# STM32H7RSxx register map
File version: 0.2
CPU: CM7 r0p1, little endian, MPU, FPU, 4 interrupt priority bits
Registers are 32-bit, read-write, reset 0x0 unless marked. A register's access mark holds for its fields unless they carry their own. Offsets are from the block's base; [hi:lo] are bit positions; lines under a group give offsets from that group; {n}, {i} and the like mark numbered series; 'fields as' and 'values as' point back to an identical list; <NAME> marks a mode.

## ADC1 — ADC register block
Base 0x40022000
Same registers: ADC2 0x40022100
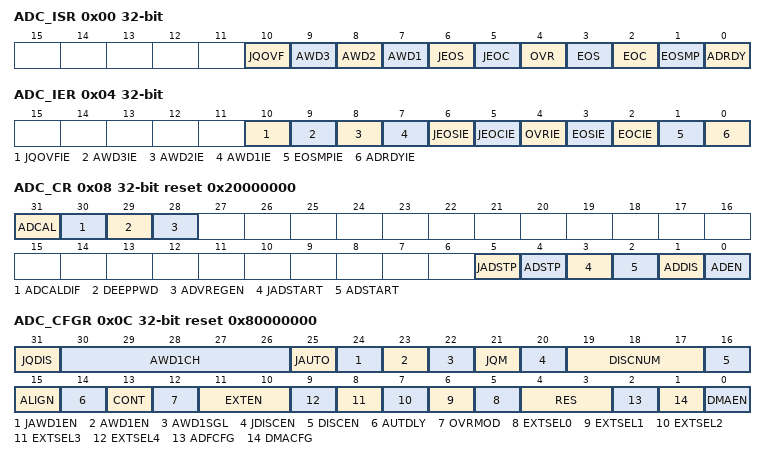
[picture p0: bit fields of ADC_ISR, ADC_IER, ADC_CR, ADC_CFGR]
0x00 ADC_ISR — ADC interrupt and status register
  [10] JQOVF — Injected context queue overflow This bit is set by hardware when an Overflow of the Injected Queue of Context occurs. It is cleared by software writing 1 to it. Refer to Section 25.4.21: Queue of context for injected conversions for more information.
    0=No injected context queue overflow occurred (or the flag event was already acknowledged and cleared by software); 1=Injected context queue overflow has occurred
  [9] AWD3 — Analog watchdog 3 flag This bit is set by hardware when the converted voltage crosses the values programmed in the fields LT3[7:0] and HT3[7:0] of ADC_TR3 register. It is cleared by software writing 1 to it.
    0=No analog watchdog 3 event occurred (or the flag event was already acknowledged and cleared by software); 1=Analog watchdog 3 event occurred
  [8] AWD2 — Analog watchdog 2 flag This bit is set by hardware when the converted voltage crosses the values programmed in the fields LT2[7:0] and HT2[7:0] of ADC_TR2 register. It is cleared by software writing 1 to it.
    0=No analog watchdog 2 event occurred (or the flag event was already acknowledged and cleared by software); 1=Analog watchdog 2 event occurred
  [7] AWD1 — Analog watchdog 1 flag This bit is set by hardware when the converted voltage crosses the values programmed in the fields LT1[11:0] and HT1[11:0] of ADC_TR1 register. It is cleared by software. writing 1 to it.
    0=No analog watchdog 1 event occurred (or the flag event was already acknowledged and cleared by software); 1=Analog watchdog 1 event occurred
  [6] JEOS — Injected channel end of sequence flag This bit is set by hardware at the end of the conversions of all injected channels in the group. It is cleared by software writing 1 to it.
    0=Injected conversion sequence not complete (or the flag event was already acknowledged and cleared by software); 1=Injected conversions complete
  [5] JEOC — Injected channel end of conversion flag This bit is set by hardware at the end of each injected conversion of a channel when a new data is available in the corresponding ADC_JDRy register. It is cleared by software writing 1 to it or by reading the corresponding ADC_JDRy register
    0=Injected channel conversion not complete (or the flag event was already acknowledged and cleared by software); 1=Injected channel conversion complete
  [4] OVR — ADC overrun This bit is set by hardware when an overrun occurs on a regular channel, meaning that a new conversion has completed while the EOC flag was already set. It is cleared by software writing 1 to it.
    0=No overrun occurred (or the flag event was already acknowledged and cleared by software); 1=Overrun has occurred
  [3] EOS — End of regular sequence flag This bit is set by hardware at the end of the conversions of a regular sequence of channels. It is cleared by software writing 1 to it.
    0=Regular Conversions sequence not complete (or the flag event was already acknowledged and cleared by software); 1=Regular Conversions sequence complete
  [2] EOC — End of conversion flag This bit is set by hardware at the end of each regular conversion of a channel when a new data is available in the ADC_DR register. It is cleared by software writing 1 to it or by reading the ADC_DR register
    0=Regular channel conversion not complete (or the flag event was already acknowledged and cleared by software); 1=Regular channel conversion complete
  [1] EOSMP — End of sampling flag This bit is set by hardware during the conversion of any channel (only for regular channels), at the end of the sampling phase.
    0=not at the end of the sampling phase (or the flag event was already acknowledged and cleared by software); 1=End of sampling phase reached
  [0] ADRDY — ADC ready This bit is set by hardware after the ADC has been enabled (ADEN = 1) and when the ADC reaches a state where it is ready to accept conversion requests. It is cleared by software writing 1 to it.
    0=ADC not yet ready to start conversion (or the flag event was already acknowledged and cleared by software); 1=ADC is ready to start conversion
0x04 ADC_IER — ADC interrupt enable register
  [10] JQOVFIE — Injected context queue overflow interrupt enable This bit is set and cleared by software to enable/disable the Injected Context Queue Overflow interrupt. Note: The software is allowed to write this bit only when JADSTART = 0 (which ensures that no injected conversion is ongoing).
    0=Injected Context Queue Overflow interrupt disabled; 1=Injected Context Queue Overflow interrupt enabled. An interrupt is generated when the JQOVF bit is set.
  [9] AWD3IE — Analog watchdog 3 interrupt enable This bit is set and cleared by software to enable/disable the analog watchdog 2 interrupt. Note: The software is allowed to write this bit only when ADSTART = 0 and JADSTART = 0 (which ensures that no conversion is ongoing).
    0=Analog watchdog 3 interrupt disabled; 1=Analog watchdog 3 interrupt enabled
  [8] AWD2IE — Analog watchdog 2 interrupt enable This bit is set and cleared by software to enable/disable the analog watchdog 2 interrupt. Note: The software is allowed to write this bit only when ADSTART = 0 and JADSTART = 0 (which ensures that no conversion is ongoing).
    0=Analog watchdog 2 interrupt disabled; 1=Analog watchdog 2 interrupt enabled
  [7] AWD1IE — Analog watchdog 1 interrupt enable This bit is set and cleared by software to enable/disable the analog watchdog 1 interrupt. Note: The software is allowed to write this bit only when ADSTART = 0 and JADSTART = 0 (which ensures that no conversion is ongoing).
    0=Analog watchdog 1 interrupt disabled; 1=Analog watchdog 1 interrupt enabled
  [6] JEOSIE — End of injected sequence of conversions interrupt enable This bit is set and cleared by software to enable/disable the end of injected sequence of conversions interrupt. Note: The software is allowed to write this bit only when JADSTART = 0 (which ensures that no injected conversion is ongoing).
    0=JEOS interrupt disabled; 1=JEOS interrupt enabled. An interrupt is generated when the JEOS bit is set.
  [5] JEOCIE — End of injected conversion interrupt enable This bit is set and cleared by software to enable/disable the end of an injected conversion interrupt. Note: The software is allowed to write this bit only when JADSTART = 0 (which ensures that no injected conversion is ongoing).
    0=JEOC interrupt disabled; 1=JEOC interrupt enabled. An interrupt is generated when the JEOC bit is set.
  [4] OVRIE — Overrun interrupt enable This bit is set and cleared by software to enable/disable the Overrun interrupt of a regular conversion. Note: The software is allowed to write this bit only when ADSTART = 0 (which ensures that no regular conversion is ongoing).
    0=Overrun interrupt disabled; 1=Overrun interrupt enabled. An interrupt is generated when the OVR bit is set.
  [3] EOSIE — End of regular sequence of conversions interrupt enable This bit is set and cleared by software to enable/disable the end of regular sequence of conversions interrupt. Note: The software is allowed to write this bit only when ADSTART = 0 (which ensures that no regular conversion is ongoing).
    0=EOS interrupt disabled; 1=EOS interrupt enabled. An interrupt is generated when the EOS bit is set.
  [2] EOCIE — End of regular conversion interrupt enable This bit is set and cleared by software to enable/disable the end of a regular conversion interrupt. Note: The software is allowed to write this bit only when ADSTART = 0 (which ensures that no regular conversion is ongoing).
    0=EOC interrupt disabled; 1=EOC interrupt enabled. An interrupt is generated when the EOC bit is set.
  [1] EOSMPIE — End of sampling flag interrupt enable for regular conversions This bit is set and cleared by software to enable/disable the end of the sampling phase interrupt for regular conversions. Note: The software is allowed to write this bit only when ADSTART = 0 (which ensures that no regular conversion is ongoing).
    0=EOSMP interrupt disabled; 1=EOSMP interrupt enabled. An interrupt is generated when the EOSMP bit is set.
  [0] ADRDYIE — ADC ready interrupt enable This bit is set and cleared by software to enable/disable the ADC Ready interrupt. Note: The software is allowed to write this bit only when ADSTART = 0 and JADSTART = 0 (which ensures that no conversion is ongoing).
    0=ADRDY interrupt disabled; 1=ADRDY interrupt enabled. An interrupt is generated when the ADRDY bit is set.
0x08 ADC_CR reset 0x20000000 — ADC control register
  [31] ADCAL — ADC calibration This bit is set by software to start the calibration of the ADC. Program first the bit ADCALDIF to determine if this calibration applies for Single-ended or Differential inputs mode. It is cleared by hardware after calibration is complete. Note: The software is allowed to launch a calibration by setting ADCAL only when ADEN = 0. Note: The software is allowed to update the calibration factor by writing ADC_CALFACT only when ADEN = 1 and ADSTART = 0 and JADSTART = 0 (ADC enabled and no conversion is ongoing)
    0=Calibration complete; 1=Write 1 to calibrate the ADC. Read at 1 means that a calibration in progress.
  [30] ADCALDIF — Differential mode for calibration This bit is set and cleared by software to configure the Single-ended or Differential inputs mode for the calibration. Note: The software is allowed to write this bit only when the ADC is disabled and is not calibrating (ADCAL = 0, JADSTART = 0, JADSTP = 0, ADSTART = 0, ADSTP = 0, ADDIS = 0 and ADEN = 0).
    0=Writing ADCAL launches a calibration in Single-ended inputs mode; 1=Writing ADCAL launches a calibration in Differential inputs mode
  [29] DEEPPWD — Deep-power-down enable This bit is set and cleared by software to put the ADC in Deep-power-down mode. Note: The software is allowed to write this bit only when the ADC is disabled (ADCAL = 0, JADSTART = 0, JADSTP = 0, ADSTART = 0, ADSTP = 0, ADDIS = 0 and ADEN = 0).
    0=ADC not in Deep-power down; 1=ADC in Deep-power-down (default reset state)
  [28] ADVREGEN — ADC voltage regulator enable This bits is set by software to enable the ADC voltage regulator. Before performing any operation such as launching a calibration or enabling the ADC, the ADC voltage regulator must first be enabled and the software must wait for the regulator start-up time. For more details about the ADC voltage regulator enable and disable sequences, refer to Section 25.4.6: ADC Deep-power-down mode (DEEPPWD) and ADC voltage regulator (ADVREGEN). The software can program this bit field only when the ADC is disabled (ADCAL = 0, JADSTART = 0, ADSTART = 0, ADSTP = 0, ADDIS = 0 and ADEN = 0).
    0=ADC Voltage regulator disabled; 1=ADC Voltage regulator enabled
  [5] JADSTP — ADC stop of injected conversion command This bit is set by software to stop and discard an ongoing injected conversion (JADSTP Command). It is cleared by hardware when the conversion is effectively discarded and the ADC injected sequence and triggers can be re-configured. The ADC is then ready to accept a new start of injected conversions (JADSTART command). Note: The software is allowed to set JADSTP only when JADSTART = 1 and ADDIS = 0 (ADC is enabled and eventually converting an injected conversion and there is no pending request to disable the ADC) Note: In Auto-injection mode (JAUTO = 1), setting ADSTP bit aborts both regular and injected conversions (do not use JADSTP)
    0=No ADC stop injected conversion command ongoing; 1=Write 1 to stop injected conversions ongoing. Read 1 means that an ADSTP command is in progress.
  [4] ADSTP — ADC stop of regular conversion command This bit is set by software to stop and discard an ongoing regular conversion (ADSTP Command). It is cleared by hardware when the conversion is effectively discarded and the ADC regular sequence and triggers can be re-configured. The ADC is then ready to accept a new start of regular conversions (ADSTART command). Note: The software is allowed to set ADSTP only when ADSTART = 1 and ADDIS = 0 (ADC is enabled and eventually converting a regular conversion and there is no pending request to disable the ADC). In auto-injection mode (JAUTO = 1), setting ADSTP bit aborts both regular and injected conversions (do not use JADSTP).
    0=No ADC stop regular conversion command ongoing; 1=Write 1 to stop regular conversions ongoing. Read 1 means that an ADSTP command is in progress.
  [3] JADSTART — ADC start of injected conversion This bit is set by software to start ADC conversion of injected channels. Depending on the configuration bits JEXTEN, a conversion immediately starts (software trigger configuration) or once an injected hardware trigger event occurs (hardware trigger configuration). It is cleared by hardware: in Single conversion mode when software trigger is selected (JEXTSEL = 0x0): at the assertion of the End of Injected Conversion Sequence (JEOS) flag. in all cases: after the execution of the JADSTP command, at the same time that JADSTP is cleared by hardware. Note: The software is allowed to set JADSTART only when ADEN = 1 and ADDIS = 0 (ADC is enabled and there is no pending request to disable the ADC). Note: In auto-injection mode (JAUTO = 1), regular and auto-injected conversions are started by setting bit ADSTART (JADSTART must be kept cleared)
    0=No ADC injected conversion is ongoing; 1=Write 1 to start injected conversions. Read 1 means that the ADC is operating and eventually converting an injected channel.
  [2] ADSTART — ADC start of regular conversion This bit is set by software to start ADC conversion of regular channels. Depending on the configuration bits EXTEN, a conversion immediately starts (software trigger configuration) or once a regular hardware trigger event occurs (hardware trigger configuration). It is cleared by hardware: in Single conversion mode when software trigger is selected (EXTSEL = 0x0): at the assertion of the End of Regular Conversion Sequence (EOS) flag. in all cases: after the execution of the ADSTP command, at the same time that ADSTP is cleared by hardware. Note: The software is allowed to set ADSTART only when ADEN = 1 and ADDIS = 0 (ADC is enabled and there is no pending request to disable the ADC) Note: In auto-injection mode (JAUTO = 1), regular and auto-injected conversions are started by setting bit ADSTART (JADSTART must be kept cleared)
    0=No ADC regular conversion is ongoing; 1=Write 1 to start regular conversions. Read 1 means that the ADC is operating and eventually converting a regular channel.
  [1] ADDIS — ADC disable command This bit is set by software to disable the ADC (ADDIS command) and put it into power-down state (OFF state). It is cleared by hardware once the ADC is effectively disabled (ADEN is also cleared by hardware at this time). Note: The software is allowed to set ADDIS only when ADEN = 1 and both ADSTART = 0 and JADSTART = 0 (which ensures that no conversion is ongoing)
    0=no ADDIS command ongoing; 1=Write 1 to disable the ADC. Read 1 means that an ADDIS command is in progress.
  [0] ADEN — ADC enable control This bit is set by software to enable the ADC. The ADC is effectively ready to operate once the flag ADRDY has been set. It is cleared by hardware when the ADC is disabled, after the execution of the ADDIS command. Note: The software is allowed to set ADEN only when all bits of ADC_CR registers are 0 (ADCAL = 0, JADSTART = 0, ADSTART = 0, ADSTP = 0, ADDIS = 0 and ADEN = 0) except for bit ADVREGEN which must be 1 (and the software must have wait for the startup time of the voltage regulator)
    0=ADC is disabled (OFF state); 1=Write 1 to enable the ADC
0x0C ADC_CFGR reset 0x80000000 — ADC configuration register
  [31] JQDIS — Injected queue disable This bit is set and cleared by software to disable the injected queue mechanism: Note: The software is allowed to write this bit only when ADSTART = 0 and JADSTART = 0 (which ensures that no regular nor injected conversion is ongoing). Note: A set or reset of JQDIS bit causes the injected queue to be flushed and the JSQR register is cleared.
    0=Injected queue enabled; 1=Injected queue disabled
  [30:26] AWD1CH — Analog watchdog 1 channel selection These bits are set and cleared by software. They select the input channel to be guarded by the analog watchdog. ..... others: reserved, must not be used Note: Some channels are not connected physically. Keep the corresponding AWD1CH[4:0] setting to the reset value. Note: The channel selected by AWD1CH must be also selected into the SQRi or JSQRi registers. Note: The software is allowed to write these bits only when ADSTART = 0 and JADSTART = 0 (which ensures that no conversion is ongoing).
    0=ADC analog input channel 0 monitored by AWD1 (available on ADC1 only); 1=ADC analog input channel 1 monitored by AWD1; 18=ADC analog input channel 18 monitored by AWD1
  [25] JAUTO — Automatic injected group conversion This bit is set and cleared by software to enable/disable automatic injected group conversion after regular group conversion. Note: The software is allowed to write this bit only when ADSTART = 0 and JADSTART = 0 (which ensures that no regular nor injected conversion is ongoing). Note: When dual mode is enabled (DUAL bits in ADC_CCR register are not equal to zero), the bit JAUTO of the slave ADC is no more writable and its content is equal to the bit JAUTO of the master ADC.
    0=Automatic injected group conversion disabled; 1=Automatic injected group conversion enabled
  [24] JAWD1EN — Analog watchdog 1 enable on injected channels This bit is set and cleared by software Note: The software is allowed to write this bit only when JADSTART = 0 (which ensures that no injected conversion is ongoing).
    0=Analog watchdog 1 disabled on injected channels; 1=Analog watchdog 1 enabled on injected channels
  [23] AWD1EN — Analog watchdog 1 enable on regular channels This bit is set and cleared by software Note: The software is allowed to write this bit only when ADSTART = 0 (which ensures that no regular conversion is ongoing).
    0=Analog watchdog 1 disabled on regular channels; 1=Analog watchdog 1 enabled on regular channels
  [22] AWD1SGL — Enable the watchdog 1 on a single channel or on all channels This bit is set and cleared by software to enable the analog watchdog on the channel identified by the AWD1CH[4:0] bits or on all the channels Note: The software is allowed to write these bits only when ADSTART = 0 and JADSTART = 0 (which ensures that no conversion is ongoing).
    0=Analog watchdog 1 enabled on all channels; 1=Analog watchdog 1 enabled on a single channel
  [21] JQM — JSQR queue mode This bit is set and cleared by software. It defines how an empty Queue is managed. Refer to Section 25.4.21: Queue of context for injected conversions for more information. Note: The software is allowed to write this bit only when JADSTART = 0 (which ensures that no injected conversion is ongoing). Note: When dual mode is enabled (DUAL bits in ADC_CCR register are not equal to zero), the bit JQM of the slave ADC is no more writable and its content is equal to the bit JQM of the master ADC.
    0=JSQR mode 0: The Queue is never empty and maintains the last written configuration into JSQR; 1=JSQR mode 1: The Queue can be empty and when this occurs, the software and hardware triggers of the injected sequence are both internally disabled just after the completion of the last valid injected sequence
  [20] JDISCEN — Discontinuous mode on injected channels This bit is set and cleared by software to enable/disable Discontinuous mode on the injected channels of a group. Note: The software is allowed to write this bit only when JADSTART = 0 (which ensures that no injected conversion is ongoing). Note: It is not possible to use both auto-injected mode and Discontinuous mode simultaneously: the bits DISCEN and JDISCEN must be kept cleared by software when JAUTO is set. Note: When dual mode is enabled (bits DUAL of ADC_CCR register are not equal to zero), the bit JDISCEN of the slave ADC is no more writable and its content is equal to the bit JDISCEN of the master ADC.
    0=Discontinuous mode on injected channels disabled; 1=Discontinuous mode on injected channels enabled
  [19:17] DISCNUM — Discontinuous mode channel count These bits are written by software to define the number of regular channels to be converted in Discontinuous mode, after receiving an external trigger. ... Note: The software is allowed to write these bits only when ADSTART = 0 (which ensures that no regular conversion is ongoing). Note: When dual mode is enabled (DUAL bits in ADC_CCR register are not equal to zero), the bits DISCNUM[2:0] of the slave ADC are no more writable and their content is equal to the bits DISCNUM[2:0] of the master ADC.
    0=1 channel; 1=2 channels; 7=8 channels
  [16] DISCEN — Discontinuous mode for regular channels This bit is set and cleared by software to enable/disable Discontinuous mode for regular channels. Note: It is not possible to have both Discontinuous mode and Continuous mode enabled: it is forbidden to set both DISCEN = 1 and CONT = 1. Note: It is not possible to use both auto-injected mode and Discontinuous mode simultaneously: the bits DISCEN and JDISCEN must be kept cleared by software when JAUTO is set. Note: The software is allowed to write this bit only when ADSTART = 0 (which ensures that no regular conversion is ongoing). Note: When dual mode is enabled (DUAL bits in ADC_CCR register are not equal to zero), the bit DISCEN of the slave ADC is no more writable and its content is equal to the bit DISCEN of the master ADC.
    0=Discontinuous mode for regular channels disabled; 1=Discontinuous mode for regular channels enabled
  [15] ALIGN — Data alignment This bit is set and cleared by software to select right or left alignment. Refer to Section : Data register, data alignment and offset (ADC_DR, OFFSET, OFFSET_CH, ALIGN). Note: The software is allowed to write this bit only when ADSTART = 0 and JADSTART = 0 (which ensures that no conversion is ongoing).
    0=Right alignment; 1=Left alignment
  [14] AUTDLY — Delayed conversion mode This bit is set and cleared by software to enable/disable the Auto Delayed Conversion mode.<sup>.</sup> Note: The software is allowed to write this bit only when ADSTART = 0 and JADSTART = 0 (which ensures that no conversion is ongoing). Note: When dual mode is enabled (DUAL bits in ADC_CCR register are not equal to zero), the bit AUTDLY of the slave ADC is no more writable and its content is equal to the bit AUTDLY of the master ADC.
    0=Auto-delayed conversion mode off; 1=Auto-delayed conversion mode on
  [13] CONT — Single / Continuous conversion mode for regular conversions This bit is set and cleared by software. If it is set, regular conversion takes place continuously until it is cleared. Note: It is not possible to have both Discontinuous mode and Continuous mode enabled: it is forbidden to set both DISCEN = 1 and CONT = 1. Note: The software is allowed to write this bit only when ADSTART = 0 (which ensures that no regular conversion is ongoing). Note: When dual mode is enabled (DUAL bits in ADC_CCR register are not equal to zero), the bit CONT of the slave ADC is no more writable and its content is equal to the bit CONT of the master ADC.
    0=Single conversion mode; 1=Continuous conversion mode
  [12] OVRMOD — Overrun mode This bit is set and cleared by software and configure the way data overrun is managed. Note: The software is allowed to write this bit only when ADSTART = 0 (which ensures that no regular conversion is ongoing).
    0=ADC_DR register is preserved with the old data when an overrun is detected; 1=ADC_DR register is overwritten with the last conversion result when an overrun is detected
  [11:10] EXTEN — External trigger enable and polarity selection for regular channels These bits are set and cleared by software to select the external trigger polarity and enable the trigger of a regular group. Note: The software is allowed to write these bits only when ADSTART = 0 (which ensures that no regular conversion is ongoing).
    0=Hardware trigger detection disabled (conversions can be launched by software); 1=Hardware trigger detection on the rising edge; 2=Hardware trigger detection on the falling edge; 3=Hardware trigger detection on both the rising and falling edges
  [n+5] EXTSEL{n} (n=0..4) — External trigger selection for regular group These bits select the external event used to trigger the start of conversion of a regular group: ... Note: The software is allowed to write these bits only when ADSTART = 0 (which ensures that no regular conversion is ongoing).
    {v}=adc_ext_trg{v} (v=0..7); 31=adc_ext_trg31
  [4:3] RES — Data resolution These bits are written by software to select the resolution of the conversion. Note: The software is allowed to write these bits only when ADSTART = 0 and JADSTART = 0 (which ensures that no conversion is ongoing).
    0=12-bit; 1=10-bit; 2=8-bit; 3=6-bit
  [2] ADFCFG — ADF mode configuration This bit is set and cleared by software to enable the ADF mode. It is effective only when DMAEN = 0. Note: To make sure no conversion is ongoing, the software is allowed to write this bit only when ADSTART = 0 and JADSTART = 0.
    0=ADF mode disabled; 1=ADF mode enabled
  [1] DMACFG — Direct memory access configuration This bit is set and cleared by software to select between two DMA modes of operation and is effective only when DMAEN = 1. For more details, refer to Section : Managing conversions using the DMA Note: The software is allowed to write this bit only when ADSTART = 0 and JADSTART = 0 (which ensures that no conversion is ongoing). Note: In dual-ADC modes, this bit is not relevant and replaced by control bit DMACFG of the ADC_CCR register.
    0=DMA One Shot mode selected; 1=DMA Circular mode selected
  [0] DMAEN — Direct memory access enable This bit is set and cleared by software to enable the generation of DMA requests. This allows to use the DMA to manage automatically the converted data. For more details, refer to Section : Managing conversions using the DMA. Note: The software is allowed to write this bit only when ADSTART = 0 and JADSTART = 0 (which ensures that no conversion is ongoing). Note: In dual-ADC modes, this bit is not relevant and replaced by control bits MDMA[1:0] of the ADC_CCR register.
    0=DMA disabled; 1=DMA enabled
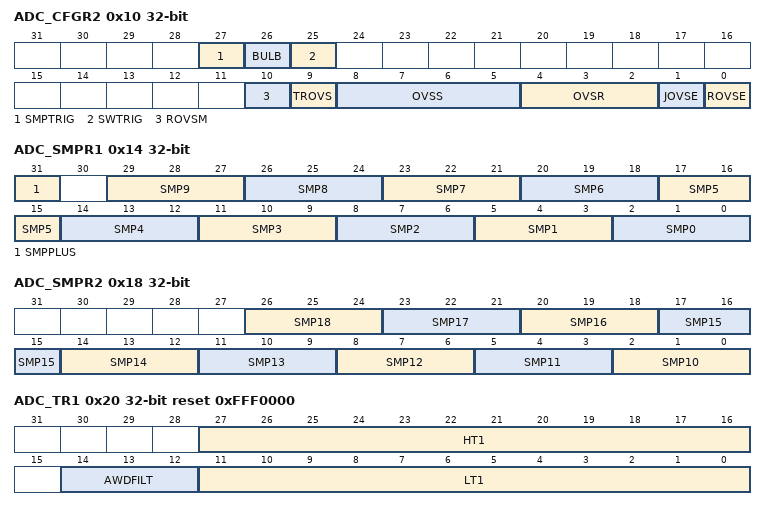
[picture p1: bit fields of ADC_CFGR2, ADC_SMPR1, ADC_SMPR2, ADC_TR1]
0x10 ADC_CFGR2 — ADC configuration register 2
  [27] SMPTRIG — Sampling time control trigger mode This bit is set and cleared by software to enable the sampling time control trigger mode. The sampling time starts on the trigger rising edge, and the conversion on the trigger falling edge. EXTEN bit should be set to 01. BULB bit must not be set when the SMPTRIG bit is set. When EXTEN bit is set to 00, set SWTRIG to start the sampling and clear SWTRIG bit to start the conversion. Note: The software is allowed to write this bit only when ADSTART = 0 (which ensures that no conversion is ongoing).
    0=Sampling time control trigger mode disabled; 1=Sampling time control trigger mode enabled
  [26] BULB — Bulb sampling mode This bit is set and cleared by software to enable the bulb sampling mode. SAMPTRIG bit must not be set when the BULB bit is set. The very first ADC conversion is performed with the sampling time specified in SMPx bits. Note: The software is allowed to write this bit only when ADSTART = 0 (which ensures that no conversion is ongoing).
    0=Bulb sampling mode disabled; 1=Bulb sampling mode enabled. The sampling period starts just after the previous end of conversion.
  [25] SWTRIG — Software trigger bit for sampling time control trigger mode This bit is set and cleared by software to enable the bulb sampling mode. Note: The software is allowed to write this bit only when ADSTART = 0 (which ensures that no conversion is ongoing).
    0=Software trigger starts the conversion for sampling time control trigger mode; 1=Software trigger starts the sampling for sampling time control trigger mode
  [10] ROVSM — Regular Oversampling mode This bit is set and cleared by software to select the regular oversampling mode. Note: The software is allowed to write this bit only when ADSTART = 0 (which ensures that no conversion is ongoing).
    0=Continued mode: When injected conversions are triggered, the oversampling is temporary stopped and continued after the injection sequence (oversampling buffer is maintained during injected sequence); 1=Resumed mode: When injected conversions are triggered, the current oversampling is aborted and resumed from start after the injection sequence (oversampling buffer is zeroed by injected sequence start)
  [9] TROVS — Triggered Regular Oversampling This bit is set and cleared by software to enable triggered oversampling Note: The software is allowed to write this bit only when ADSTART = 0 (which ensures that no conversion is ongoing).
    0=All oversampled conversions for a channel are done consecutively following a trigger; 1=Each oversampled conversion for a channel needs a new trigger
  [8:5] OVSS — Oversampling shift This bitfield is set and cleared by software to define the right shifting applied to the raw oversampling result. Other codes reserved Note: The software is allowed to write these bits only when ADSTART = 0 (which ensures that no conversion is ongoing).
    0=No shift; 1=Shift 1-bit; {v}=Shift {v}-bits (v=2..8)
  [4:2] OVSR — Oversampling ratio This bitfield is set and cleared by software to define the oversampling ratio. Note: The software is allowed to write these bits only when ADSTART = 0 (which ensures that no conversion is ongoing).
    0=2x; 1=4x; 2=8x; 3=16x; 4=32x; 5=64x; 6=128x; 7=256x
  [1] JOVSE — Injected Oversampling Enable This bit is set and cleared by software to enable injected oversampling. Note: The software is allowed to write this bit only when ADSTART = 0 and JADSTART = 0 (which ensures that no conversion is ongoing)
    0=Injected Oversampling disabled; 1=Injected Oversampling enabled
  [0] ROVSE — Regular Oversampling Enable This bit is set and cleared by software to enable regular oversampling. Note: The software is allowed to write this bit only when ADSTART = 0 and JADSTART = 0 (which ensures that no conversion is ongoing)
    0=Regular Oversampling disabled; 1=Regular Oversampling enabled
0x14 ADC_SMPR1 — ADC sample time register 1
  [31] SMPPLUS — Addition of one clock cycle to the sampling time. To make sure no conversion is ongoing, the software is allowed to write this bit only when ADSTART = 0 and JADSTART = 0.
    1=2.5 ADC clock cycle sampling time becomes 3.5 ADC clock cycles for the ADC_SMPR1 and ADC_SMPR2 registers; 0=The sampling time remains set to 2.5 ADC clock cycles remains
  [3n+2:3n] SMP{n} (n=0..9) — Channel x sampling time selection These bits are written by software to select the sampling time individually for each channel. During sample cycles, the channel selection bits must remain unchanged. Note: The software is allowed to write these bits only when ADSTART = 0 and JADSTART = 0 (which ensures that no conversion is ongoing). Note: Some channels are not connected physically. Keep the corresponding SMPx[2:0] setting to the reset value.
    0=2.5 ADC clock cycles; 1=6.5 ADC clock cycles; 2=12.5 ADC clock cycles; 3=24.5 ADC clock cycles; 4=47.5 ADC clock cycles; 5=92.5 ADC clock cycles; 6=247.5 ADC clock cycles; 7=640.5 ADC clock cycles
0x18 ADC_SMPR2 — ADC sample time register 2
  [all] fields
    values as ADC_SMPR1.SMP0
  [3n-28:3n-30] SMP{n} (n=10..18) — Channel x sampling time selection These bits are written by software to select the sampling time individually for each channel. During sampling cycles, the channel selection bits must remain unchanged. Note: The software is allowed to write these bits only when ADSTART = 0 and JADSTART = 0 (which ensures that no conversion is ongoing). Note: Some channels are not connected physically. Keep the corresponding SMPx[2:0] setting to the reset value.
0x20 ADC_TR1 reset 0xFFF0000 — ADC watchdog threshold register 1
  [27:16] HT1 — Analog watchdog 1 higher threshold These bits are written by software to define the higher threshold for the analog watchdog 1. Refer to Section 25.4.29: Analog window watchdog (AWD1EN, JAWD1EN, AWD1SGL, AWD1CH, AWD2CH, AWD3CH, AWD_HTx, AWD_LTx, AWDx) Note: The software is allowed to write these bits only when ADSTART = 0 and JADSTART = 0 (which ensures that no conversion is ongoing).
  [14:12] AWDFILT — Analog watchdog filtering parameter This bit is set and cleared by software. ... Note: The software is allowed to write this bit only when ADSTART = 0 (which ensures that no conversion is ongoing).
    0=No filtering; 1=two consecutive detection generates an AWDx flag or an interrupt; 7=Eight consecutive detection generates an AWDx flag or an interrupt
  [11:0] LT1 — Analog watchdog 1 lower threshold These bits are written by software to define the lower threshold for the analog watchdog 1. Refer to Section 25.4.29: Analog window watchdog (AWD1EN, JAWD1EN, AWD1SGL, AWD1CH, AWD2CH, AWD3CH, AWD_HTx, AWD_LTx, AWDx) Note: The software is allowed to write these bits only when ADSTART = 0 and JADSTART = 0 (which ensures that no conversion is ongoing).
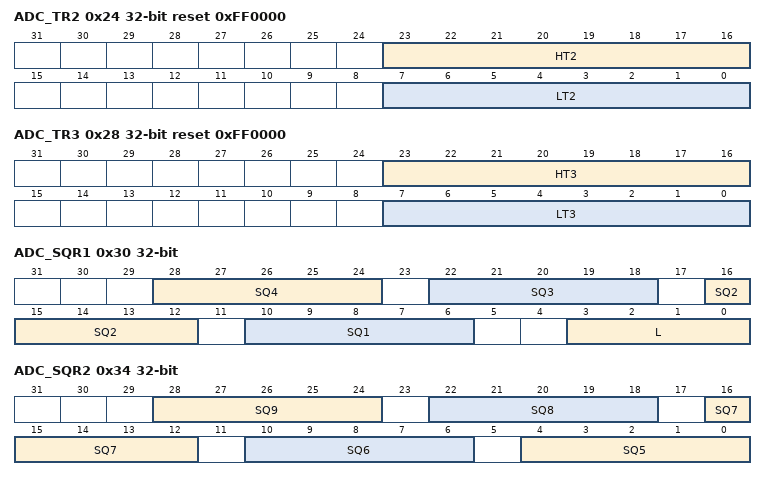
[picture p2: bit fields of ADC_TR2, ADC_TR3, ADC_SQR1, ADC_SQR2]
0x24 ADC_TR2 reset 0xFF0000 — ADC watchdog threshold register 2
  [23:16] HT2 — Analog watchdog 2 higher threshold These bits are written by software to define the higher threshold for the analog watchdog 2. Refer to Section 25.4.29: Analog window watchdog (AWD1EN, JAWD1EN, AWD1SGL, AWD1CH, AWD2CH, AWD3CH, AWD_HTx, AWD_LTx, AWDx) Note: The software is allowed to write these bits only when ADSTART = 0 and JADSTART = 0 (which ensures that no conversion is ongoing).
  [7:0] LT2 — Analog watchdog 2 lower threshold These bits are written by software to define the lower threshold for the analog watchdog 2. Refer to Section 25.4.29: Analog window watchdog (AWD1EN, JAWD1EN, AWD1SGL, AWD1CH, AWD2CH, AWD3CH, AWD_HTx, AWD_LTx, AWDx) Note: The software is allowed to write these bits only when ADSTART = 0 and JADSTART = 0 (which ensures that no conversion is ongoing).
0x28 ADC_TR3 reset 0xFF0000 — ADC watchdog threshold register 3
  [23:16] HT3 — Analog watchdog 3 higher threshold These bits are written by software to define the higher threshold for the analog watchdog 3. Refer to Section 25.4.29: Analog window watchdog (AWD1EN, JAWD1EN, AWD1SGL, AWD1CH, AWD2CH, AWD3CH, AWD_HTx, AWD_LTx, AWDx) Note: The software is allowed to write these bits only when ADSTART = 0 and JADSTART = 0 (which ensures that no conversion is ongoing).
  [7:0] LT3 — Analog watchdog 3 lower threshold These bits are written by software to define the lower threshold for the analog watchdog 3. This watchdog compares the 8-bit of LT3 with the 8 MSB of the converted data. Note: The software is allowed to write these bits only when ADSTART = 0 and JADSTART = 0 (which ensures that no conversion is ongoing).
0x30 ADC_SQR1 — ADC regular sequence register 1
  [28:24] SQ4 — 4th conversion in regular sequence These bits are written by software with the channel number (0 to 18) assigned as the 4th in the regular conversion sequence. Note: The software is allowed to write these bits only when ADSTART = 0 (which ensures that no regular conversion is ongoing).
  [22:18] SQ3 — 3rd conversion in regular sequence These bits are written by software with the channel number (0 to 18) assigned as the 3rd in the regular conversion sequence. Note: The software is allowed to write these bits only when ADSTART = 0 (which ensures that no regular conversion is ongoing).
  [16:12] SQ2 — 2nd conversion in regular sequence These bits are written by software with the channel number (0 to 18) assigned as the 2nd in the regular conversion sequence. Note: The software is allowed to write these bits only when ADSTART = 0 (which ensures that no regular conversion is ongoing).
  [10:6] SQ1 — 1st conversion in regular sequence These bits are written by software with the channel number (0 to 18) assigned as the 1st in the regular conversion sequence. Note: The software is allowed to write these bits only when ADSTART = 0 (which ensures that no regular conversion is ongoing).
  [3:0] L — Regular channel sequence length These bits are written by software to define the total number of conversions in the regular channel conversion sequence. ... Note: The software is allowed to write these bits only when ADSTART = 0 (which ensures that no regular conversion is ongoing).
    0=1 conversion; 1=2 conversions; 15=16 conversions
0x34 ADC_SQR2 — ADC regular sequence register 2
  [28:24] SQ9 — 9th conversion in regular sequence These bits are written by software with the channel number (0 to 18) assigned as the 9th in the regular conversion sequence. Note: The software is allowed to write these bits only when ADSTART = 0 (which ensures that no regular conversion is ongoing).
  [22:18] SQ8 — 8th conversion in regular sequence These bits are written by software with the channel number (0 to 18) assigned as the 8th in the regular conversion sequence Note: The software is allowed to write these bits only when ADSTART = 0 (which ensures that no regular conversion is ongoing).
  [16:12] SQ7 — 7th conversion in regular sequence These bits are written by software with the channel number (0 to 18) assigned as the 7th in the regular conversion sequence. Note: The software is allowed to write these bits only when ADSTART = 0 (which ensures that no regular conversion is ongoing).
  [10:6] SQ6 — 6th conversion in regular sequence These bits are written by software with the channel number (0 to 18) assigned as the 6th in the regular conversion sequence. Note: The software is allowed to write these bits only when ADSTART = 0 (which ensures that no regular conversion is ongoing).
  [4:0] SQ5 — 5th conversion in regular sequence These bits are written by software with the channel number (0 to 18) assigned as the 5th in the regular conversion sequence. Note: The software is allowed to write these bits only when ADSTART = 0 (which ensures that no regular conversion is ongoing).
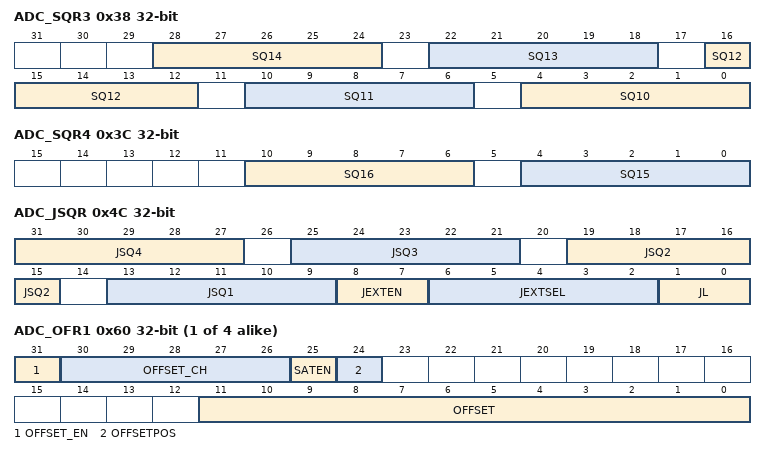
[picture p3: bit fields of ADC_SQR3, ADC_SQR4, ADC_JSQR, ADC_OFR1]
0x38 ADC_SQR3 — ADC regular sequence register 3
  [6n-56:6n-60] SQ{n} (n=10..14) — {n}th conversion in regular sequence These bits are written by software with the channel number (0 to 18) assigned as the {n}th in the regular conversion sequence. Note: The software is allowed to write these bits only when ADSTART = 0 (which ensures that no regular conversion is ongoing).
0x3C ADC_SQR4 — ADC regular sequence register 4
  [10:6] SQ16 — 16th conversion in regular sequence These bits are written by software with the channel number (0 to 18) assigned as the 16th in the regular conversion sequence. Note: The software is allowed to write these bits only when ADSTART = 0 (which ensures that no regular conversion is ongoing).
  [4:0] SQ15 — 15th conversion in regular sequence These bits are written by software with the channel number (0 to 18) assigned as the 15th in the regular conversion sequence. Note: The software is allowed to write these bits only when ADSTART = 0 (which ensures that no regular conversion is ongoing).
0x40 ADC_DR ro — ADC regular data register
  [15:0] RDATA — Regular data converted These bits are read-only. They contain the conversion result from the last converted regular channel. The data are left- or right-aligned as described in Section 25.4.26: Data management.
0x4C ADC_JSQR — ADC injected sequence register
  [31:27] JSQ4 — 4th conversion in the injected sequence These bits are written by software with the channel number (0 to 18) assigned as the 4th in the injected conversion sequence. Note: The software is allowed to write these bits only when JADSTART = 0 (which ensures that no injected conversion is ongoing).
  [25:21] JSQ3 — 3rd conversion in the injected sequence These bits are written by software with the channel number (0 to 18) assigned as the 3rd in the injected conversion sequence. Note: The software is allowed to write these bits only when JADSTART = 0 (which ensures that no injected conversion is ongoing).
  [19:15] JSQ2 — 2nd conversion in the injected sequence These bits are written by software with the channel number (0 to 18) assigned as the 2nd in the injected conversion sequence. Note: The software is allowed to write these bits only when JADSTART = 0 (which ensures that no injected conversion is ongoing).
  [13:9] JSQ1 — 1st conversion in the injected sequence These bits are written by software with the channel number (0 to 18) assigned as the 1st in the injected conversion sequence. Note: The software is allowed to write these bits only when JADSTART = 0 (which ensures that no injected conversion is ongoing).
  [8:7] JEXTEN — External trigger enable and polarity selection for injected channels These bits are set and cleared by software to select the external trigger polarity and enable the trigger of an injected group. Note: The software is allowed to write these bits only when JADSTART = 0 (which ensures that no injected conversion is ongoing). Note: If JQM = 1 and if the Queue of Context becomes empty, the software and hardware triggers of the injected sequence are both internally disabled (refer to Section 25.4.21: Queue of context for injected conversions)
    0=If JQDIS = 0 (queue enabled), hardware and software trigger detection disabled. Otherwise, the queue is disabled as well as hardware trigger detection (conversions can be launched by software); 1=Hardware trigger detection on the rising edge; 2=Hardware trigger detection on the falling edge; 3=Hardware trigger detection on both the rising and falling edges
  [6:2] JEXTSEL — External Trigger Selection for injected group These bits select the external event used to trigger the start of conversion of an injected group: ... Note: The software is allowed to write these bits only when JADSTART = 0 (which ensures that no injected conversion is ongoing).
    {v}=adc_jext_trg{v} (v=0..7); 31=adc_jext_trg31
  [1:0] JL — Injected channel sequence length These bits are written by software to define the total number of conversions in the injected channel conversion sequence. Note: The software is allowed to write these bits only when JADSTART = 0 (which ensures that no injected conversion is ongoing).
    0=1 conversion; 1=2 conversions; 2=3 conversions; 3=4 conversions
{0x5C+4i} ADC_OFR{i} (i=1..4) — ADC offset {i} register
  [31] OFFSET_EN — Offset y enable This bit is written by software to enable or disable the offset programmed into bits OFFSET[11:0]. Note: The software is allowed to write this bit only when ADSTART = 0 and JADSTART = 0 (which ensures that no conversion is ongoing).
  [30:26] OFFSET_CH — Channel selection for the data offset y These bits are written by software to define the channel to which the offset programmed into bits OFFSET[11:0] applies. Note: The software is allowed to write these bits only when ADSTART = 0 and JADSTART = 0 (which ensures that no conversion is ongoing). Note: Some channels are not connected physically and must not be selected for the data offset y. Note: If OFFSET_EN is set, it is not allowed to select the same channel for different ADC_OFRy registers.
  [25] SATEN — Saturation enable This bit is set and cleared by software to enable the saturation at 0x000 and 0xFFF for the offset function. Note: The software is allowed to write these bits only when ADSTART = 0 and JADSTART = 0 (which ensures that no conversion is ongoing).
    0=No saturation control, offset result can be signed; 1=Saturation enabled, offset result unsigned and saturated at 0x000 and 0xFFF
  [24] OFFSETPOS — Positive offset This bit is set and cleared by software to enable the positive offset. Note: The software is allowed to write these bits only when ADSTART = 0 and JADSTART = 0 (which ensures that no conversion is ongoing).
    0=Negative offset; 1=Positive offset
  [11:0] OFFSET — Data offset y for the channel programmed into bits OFFSET_CH[4:0] These bits are written by software to define the offset to be subtracted from the raw converted data when converting a channel (can be regular or injected). The channel to which applies the data offset must be programmed in the bits OFFSET_CH[4:0]. The conversion result can be read from in the ADC_DR (regular conversion) or from in the ADC_JDRyi registers (injected conversion). Note: The software is allowed to write these bits only when ADSTART = 0 and JADSTART = 0 (which ensures that no conversion is ongoing). If several offset (OFFSET) point to the same channel, only the offset with the lowest x value is considered for the subtraction. Note: Ex: if OFFSET1_CH[4:0] = 4 and OFFSET2_CH[4:0] = 4, this is OFFSET1[11:0] which is subtracted when converting channel 4.
{0x7C+4i} ADC_JDR{i} ro (i=1..4) — ADC injected channel {i} data register
  [15:0] JDATA — Injected data These bits are read-only. They contain the conversion result from injected channel y. The data are left -or right-aligned as described in Section 25.4.26: Data management.
0xA0 ADC_AWD2CR — ADC Analog Watchdog 2 Configuration Register
  [18:0] AWD2CH — Analog watchdog 2 channel selection These bits are set and cleared by software. They enable and select the input channels to be guarded by the analog watchdog 2. AWD2CH[i] = 0: ADC analog input channel i is not monitored by AWD2 AWD2CH[i] = 1: ADC analog input channel i is monitored by AWD2 When AWD2CH[18:0] = 000..0, the analog Watchdog 2 is disabled Note: The channels selected by AWD2CH must be also selected into the SQRi or JSQRi registers. Note: The software is allowed to write these bits only when ADSTART = 0 and JADSTART = 0 (which ensures that no conversion is ongoing). Note: Some channels are not connected physically and must not be selected for the analog watchdog.
0xA4 ADC_AWD3CR — ADC Analog Watchdog 3 Configuration Register
  [18:0] AWD3CH — Analog watchdog 3 channel selection These bits are set and cleared by software. They enable and select the input channels to be guarded by the analog watchdog 3. AWD3CH[i] = 0: ADC analog input channel i is not monitored by AWD3 AWD3CH[i] = 1: ADC analog input channel i is monitored by AWD3 When AWD3CH[18:0] = 000..0, the analog Watchdog 3 is disabled Note: The channels selected by AWD3CH must be also selected into the SQRi or JSQRi registers. Note: The software is allowed to write these bits only when ADSTART = 0 and JADSTART = 0 (which ensures that no conversion is ongoing). Note: Some channels are not connected physically and must not be selected for the analog watchdog.
0xB0 ADC_DIFSEL — ADC Differential mode Selection Register
  [18:0] DIFSEL — Differential mode for channels 18 to 0. These bits are set and cleared by software. They allow to select if a channel is configured as Single-ended or Differential mode. DIFSEL[i] = 0: ADC analog input channel is configured in Single-ended mode DIFSEL[i] = 1: ADC analog input channel i is configured in Differential mode Note: The DIFSEL bits corresponding to channels that are either connected to a single-ended I/O port or to an internal channel must be kept their reset value (Single-ended input mode). Note: The software is allowed to write these bits only when the ADC is disabled (ADCAL = 0, JADSTART = 0, JADSTP = 0, ADSTART = 0, ADSTP = 0, ADDIS = 0 and ADEN = 0).
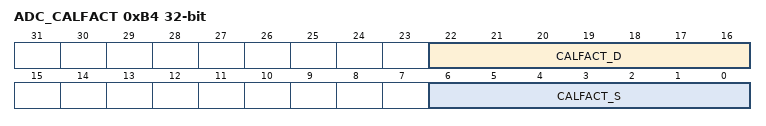
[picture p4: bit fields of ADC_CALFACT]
0xB4 ADC_CALFACT — ADC Calibration Factors
  [22:16] CALFACT_D — Calibration Factors in differential mode These bits are written by hardware or by software. Once a differential inputs calibration is complete, they are updated by hardware with the calibration factors. Software can write these bits with a new calibration factor. If the new calibration factor is different from the current one stored into the analog ADC, it is then applied once a new differential calibration is launched. Note: The software is allowed to write these bits only when ADEN = 1, ADSTART = 0 and JADSTART = 0 (ADC is enabled and no calibration is ongoing and no conversion is ongoing).
  [6:0] CALFACT_S — Calibration Factors In Single-ended mode These bits are written by hardware or by software. Once a single-ended inputs calibration is complete, they are updated by hardware with the calibration factors. Software can write these bits with a new calibration factor. If the new calibration factor is different from the current one stored into the analog ADC, it is then applied once a new single-ended calibration is launched. Note: The software is allowed to write these bits only when ADEN = 1, ADSTART = 0 and JADSTART = 0 (ADC is enabled and no calibration is ongoing and no conversion is ongoing).
0xC8 ADC_OR — ADC option register
  [0] OP0 — Option bit 0
    0=V<sub>DDCORE </sub>channel disabled; 1=V<sub>DDCORE </sub>channel enabled

## Notices in the file
Copyright (c) 2022 STMicroelectronics.
SPDX-License-Identifier: Apache-2.0
Licensed under the Apache License, Version 2.0 (the "License");
you may not use this file except in compliance with the License.
You may obtain a copy of the License at
http://www.apache.org/licenses/LICENSE-2.0
Unless required by applicable law or agreed to in writing, software
distributed under the License is distributed on an "AS IS" BASIS,
WITHOUT WARRANTIES OR CONDITIONS OF ANY KIND, either express or implied.
See the License for the specific language governing permissions and
limitations under the License.
